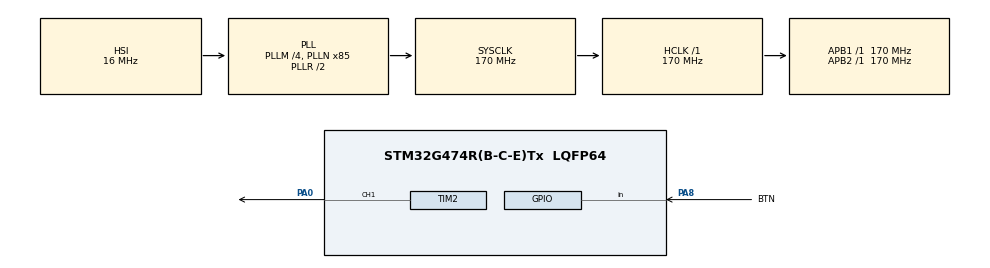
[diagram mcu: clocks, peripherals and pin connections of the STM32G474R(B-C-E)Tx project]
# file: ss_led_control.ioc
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Dma.Request0=TIM2_CH1
Dma.TIM2_CH1.0.Direction=DMA_MEMORY_TO_PERIPH
Dma.TIM2_CH1.0.EventEnable=DISABLE
Dma.TIM2_CH1.0.Instance=DMA1_Channel1
Dma.TIM2_CH1.0.MemDataAlignment=DMA_MDATAALIGN_WORD
Dma.TIM2_CH1.0.MemInc=DMA_MINC_ENABLE
Dma.TIM2_CH1.0.Mode=DMA_NORMAL
Dma.TIM2_CH1.0.PeriphDataAlignment=DMA_PDATAALIGN_WORD
Dma.TIM2_CH1.0.PeriphInc=DMA_PINC_DISABLE
Dma.TIM2_CH1.0.Polarity=HAL_DMAMUX_REQ_GEN_RISING
Dma.TIM2_CH1.0.Priority=DMA_PRIORITY_LOW
Dma.TIM2_CH1.0.RequestNumber=1
Dma.TIM2_CH1.0.SignalID=NONE
Dma.TIM2_CH1.0.SyncEnable=DISABLE
Dma.TIM2_CH1.0.SyncPolarity=HAL_DMAMUX_SYNC_NO_EVENT
Dma.TIM2_CH1.0.SyncRequestNumber=1
Dma.TIM2_CH1.0.SyncSignalID=NONE
Mcu.Family=STM32G4
Mcu.Name=STM32G474R(B-C-E)Tx
Mcu.Package=LQFP64
NVIC.DMA1_Channel1_IRQn=true\:0\:0\:false\:false\:true\:false\:true\:true
NVIC.PriorityGroup=NVIC_PRIORITYGROUP_4
PA0.Signal=S_TIM2_CH1
PA8.GPIO_Label=BTN
PA8.GPIO_PuPd=GPIO_PULLUP
PA8.Signal=GPIO_Input
ProjectManager.HeapSize=0x200
ProjectManager.StackSize=0x400
ProjectManager.TargetToolchain=STM32CubeIDE
RCC.ADC12Freq_Value=170000000
RCC.ADC345Freq_Value=170000000
RCC.AHBFreq_Value=170000000
RCC.APB1Freq_Value=170000000
RCC.APB1TimFreq_Value=170000000
RCC.APB2Freq_Value=170000000
RCC.APB2TimFreq_Value=170000000
RCC.CortexFreq_Value=170000000
RCC.EXTERNAL_CLOCK_VALUE=12288000
RCC.HCLKFreq_Value=170000000
RCC.HSE_VALUE=8000000
RCC.HSI48_VALUE=48000000
RCC.HSI_VALUE=16000000
RCC.LSE_VALUE=32768
RCC.PLLM=RCC_PLLM_DIV4
RCC.PLLN=85
RCC.SYSCLKFreq_VALUE=170000000
RCC.SYSCLKSource=RCC_SYSCLKSOURCE_PLLCLK
RCC.USBFreq_Value=170000000
RCC.VCOOutputFreq_Value=340000000
SH.S_TIM2_CH1.0=TIM2_CH1,PWM Generation1 CH1
TIM2.Channel-PWM\ Generation1\ CH1=TIM_CHANNEL_1
TIM2.PeriodNoDither=211
VP_SYS_VS_DBSignals.Mode=DisableDeadBatterySignals
VP_TIM2_VS_ClockSourceINT.Mode=Internal
board=custom

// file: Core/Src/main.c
/* USER CODE BEGIN Header */
/**
  ******************************************************************************
  * @file           : main.c
  * @brief          : Main program body
  ******************************************************************************
  * @attention
  *
  * Copyright (c) 2026 STMicroelectronics.
  * All rights reserved.
  *
  * This software is licensed under terms that can be found in the LICENSE file
  * in the root directory of this software component.
  * If no LICENSE file comes with this software, it is provided AS-IS.
  *
  ******************************************************************************
  */
/* USER CODE END Header */
#include "main.h"
#include "dma.h"
#include "tim.h"
#include "gpio.h"

/* USER CODE BEGIN PD */

#define WS2812B_0val 68 // 170 000 000 * 0.4 * 10^-6 (T0H -> T0L)
#define WS2812B_1val 136 // to samo co wyzej tylko 0.8 * 10^-6 (T1H -> T1L)
#define WS2812B_RESPULSES 40 // 8500 ale musimy to upchac to 1.25 czyli 212 cykli wiec dzielimy i
							// w zaokragleniu 40 cykli musi przemilczec

/* USER CODE END PD */

/* USER CODE BEGIN PV */

uint32_t led_info[24 + WS2812B_RESPULSES] = {0}; // inicjalizacja tablicy ktora pomiesci informacje dla
											 // jednej diody i daje zapas na poslanie resetu

/* USER CODE END PV */

void SystemClock_Config(void);

/* USER CODE BEGIN 0 */

void RGB_to_GRB(uint8_t R, uint8_t G, uint8_t B) {
	uint32_t GRB = (G << 16) | (R << 8) | B; // przesuwam odpowiednio kolory na bitach aby z RGB zrobić GRB (ledy tak odczytuja dane)

	for (int i = 23; i >= 0; i--){ // odczytuje GRB od najstarszego bitu, "tłumacze" na język ledów i wkładam do pakietu
		if (GRB & (1 << i)) { // slicing ale przez maske
			led_info[23-i] = WS2812B_1val;
		}
		else {
			led_info[23-i] = WS2812B_0val;
		}
	}

	for (int i = 24; i < (24+WS2812B_RESPULSES); i++) { // info o zakończeniu przesyłu
		led_info[i] = 0;
	}
}

/* USER CODE END 0 */

int main(void)
{

  /* MCU Configuration--------------------------------------------------------*/

  /* Reset of all peripherals, Initializes the Flash interface and the Systick. */
  HAL_Init();

  /* Configure the system clock */
  SystemClock_Config();

  /* Initialize all configured peripherals */
  MX_GPIO_Init();
  MX_DMA_Init();
  MX_TIM2_Init();
  /* USER CODE BEGIN 2 */

  uint8_t blink_steps = 0;
  uint32_t next_toggle_time = 0;
  uint8_t last_button_state = GPIO_PIN_SET;

  /* USER CODE END 2 */

  /* Infinite loop */
  while (1)
  {

    /* USER CODE BEGIN 3 */

	  uint32_t curr_time = HAL_GetTick();
	  uint32_t cycle_t3s_time = curr_time % 3000; // T = 3s

	  uint8_t red = 0;
	  uint8_t green = 0;
	  uint8_t blue = 0;

	  // 2.1.1: obsluga wyswietlania czerwonego, po 50% czasu lampka gaśnie (sygnal prostokatny)

	  if (cycle_t3s_time < 1500) {
		  red = 255;
	  }
	  else {
		  red = 0;
	  }

	  // 2.1.2: obsługa plynnego rozjasniania zielonego, rozjasnia sie proporcjonalnie do przebytego czasu cyklu

	  green = 255*(cycle_t3s_time/3000);

	  // 2.1.3: obsluga niebieskiego jest wykonywana poprzez guzik wiec zostawiam na 0

	  // ...

	  // Wykorzystuje swoja funkcje do przeslania pakietu

	  RGB_to_GRB(red,green,blue);

	  // Wysyłam pakiet do diod LED

	  HAL_TIM_PWM_Start_DMA(&htim2, TIM_CHANNEL_1, (uint32_t *)led_info, (24 + WS2812B_RESPULSES));

	  // 2.1.3:

	  uint8_t current_button_state = HAL_GPIO_ReadPin(BTN_GPIO_Port, BTN_Pin);

	  // weryfikuje, że guzik jest wciskany i nie przerywam trwajacego juz cyklu
	  if (current_button_state == GPIO_PIN_RESET && last_button_state == GPIO_PIN_SET && blink_steps == 0) {
		  blink_steps = 6; // 3 wlaczenia i 3 wylaczenia
		  next_toggle_time = curr_time + 200; // 200 ms realizuje cale mrugania w 1.2s wiec w granicy t=3s
		  blue = 255;
	  }
	  last_button_state = current_button_state;

	  if (blink_steps > 0) {
		  if (curr_time >= next_toggle_time) { // weyrifkacja czy czas kroku nie minal
			  if (blue == 255) { // jezeli tak i zalaczone to wylacz diodke lub ja zapal
				  blue = 0;
			  }
			  else {
				  blue = 255;
			  }
			  blink_steps--; // jeden krok mniej
			  next_toggle_time = curr_time + 200; // dodanie czasu dla kolejnego kroku
		  }
	  }
	  else {
		  blue = 0; // cykl sie zakonczyl wiec wylaczam diode
	  }

  }
  /* USER CODE END 3 */
}

void SystemClock_Config(void)
{
  RCC_OscInitTypeDef RCC_OscInitStruct = {0};
  RCC_ClkInitTypeDef RCC_ClkInitStruct = {0};

  /** Configure the main internal regulator output voltage
  */
  HAL_PWREx_ControlVoltageScaling(PWR_REGULATOR_VOLTAGE_SCALE1_BOOST);

  /** Initializes the RCC Oscillators according to the specified parameters
  * in the RCC_OscInitTypeDef structure.
  */
  RCC_OscInitStruct.OscillatorType = RCC_OSCILLATORTYPE_HSI;
  RCC_OscInitStruct.HSIState = RCC_HSI_ON;
  RCC_OscInitStruct.HSICalibrationValue = RCC_HSICALIBRATION_DEFAULT;
  RCC_OscInitStruct.PLL.PLLState = RCC_PLL_ON;
  RCC_OscInitStruct.PLL.PLLSource = RCC_PLLSOURCE_HSI;
  RCC_OscInitStruct.PLL.PLLM = RCC_PLLM_DIV4;
  RCC_OscInitStruct.PLL.PLLN = 85;
  RCC_OscInitStruct.PLL.PLLP = RCC_PLLP_DIV2;
  RCC_OscInitStruct.PLL.PLLQ = RCC_PLLQ_DIV2;
  RCC_OscInitStruct.PLL.PLLR = RCC_PLLR_DIV2;
  if (HAL_RCC_OscConfig(&RCC_OscInitStruct) != HAL_OK)
  {
    Error_Handler();
  }

  /** Initializes the CPU, AHB and APB buses clocks
  */
  RCC_ClkInitStruct.ClockType = RCC_CLOCKTYPE_HCLK|RCC_CLOCKTYPE_SYSCLK
                              |RCC_CLOCKTYPE_PCLK1|RCC_CLOCKTYPE_PCLK2;
  RCC_ClkInitStruct.SYSCLKSource = RCC_SYSCLKSOURCE_PLLCLK;
  RCC_ClkInitStruct.AHBCLKDivider = RCC_SYSCLK_DIV1;
  RCC_ClkInitStruct.APB1CLKDivider = RCC_HCLK_DIV1;
  RCC_ClkInitStruct.APB2CLKDivider = RCC_HCLK_DIV1;

  if (HAL_RCC_ClockConfig(&RCC_ClkInitStruct, FLASH_LATENCY_4) != HAL_OK)
  {
    Error_Handler();
  }
}

void Error_Handler(void)
{
  __disable_irq();
  while (1)
  {
  }
}
